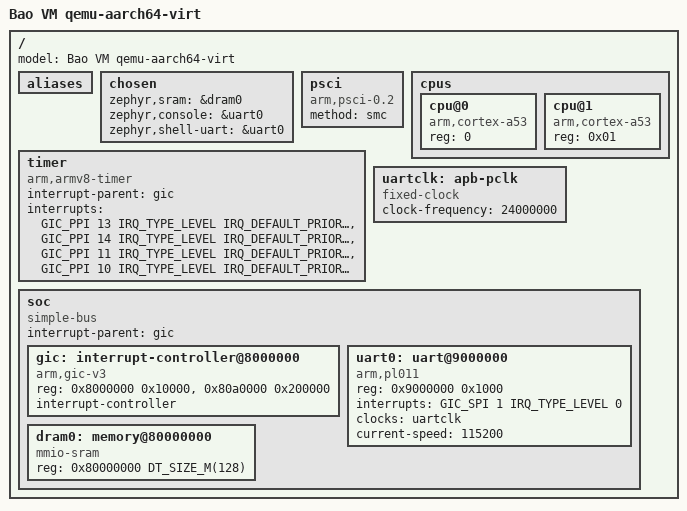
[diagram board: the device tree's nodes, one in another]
/*
 * Copyright (c) 2021 Carlo Caione <ccaione@baylibre.com>
 * SPDX-License-Identifier: Apache-2.0
 */

/dts-v1/;

#include <mem.h>
#include <zephyr/dt-bindings/interrupt-controller/arm-gic.h>

/ {
	model = "Bao VM qemu-aarch64-virt";
	#address-cells = <1>;
	#size-cells = <1>;

	aliases { };

	chosen {
		/*
		 * The SRAM node is actually located in the
		 * DRAM region of the FVP Base RevC 2xAEMv8A.
		 */
		zephyr,sram = &dram0;
		zephyr,console = &uart0;
		zephyr,shell-uart = &uart0;
	};

	psci {
		compatible = "arm,psci-0.2";
		method = "smc";
	};

	cpus {
		#address-cells = <1>;
		#size-cells = <0>;

		cpu@0 {
			device_type = "cpu";
			compatible = "arm,cortex-a53";
			reg = <0>;
		};

		cpu@1 {
			device_type = "cpu";
			compatible = "arm,cortex-a53";
			reg = <0x01>;
		};
	};

	timer {
		compatible = "arm,armv8-timer";
		interrupt-parent = <&gic>;
		interrupts = <GIC_PPI 13 IRQ_TYPE_LEVEL
			      IRQ_DEFAULT_PRIORITY>,
			     <GIC_PPI 14 IRQ_TYPE_LEVEL
			      IRQ_DEFAULT_PRIORITY>,
			     <GIC_PPI 11 IRQ_TYPE_LEVEL
			      IRQ_DEFAULT_PRIORITY>,
			     <GIC_PPI 10 IRQ_TYPE_LEVEL
			      IRQ_DEFAULT_PRIORITY>;
	};

	uartclk: apb-pclk {
		compatible = "fixed-clock";
		clock-frequency = <24000000>;
		#clock-cells = <0>;
	};

	soc {
		#address-cells = <1>;
		#size-cells = <1>;
		compatible = "simple-bus";
		ranges;
		interrupt-parent = <&gic>;

		gic: interrupt-controller@8000000 {
			compatible = "arm,gic-v3", "arm,gic";
			reg = <0x8000000 0x10000>, // GICD
			      <0x80a0000 0x200000>; // GICR
			interrupt-controller;
			#interrupt-cells = <4>;
			status = "okay";
			#address-cells = <1>;
			#size-cells = <1>;
		};

		uart0: uart@9000000 {
			compatible = "arm,pl011";
			reg = <0x9000000 0x1000>;
			status = "disabled";
			interrupts = <GIC_SPI 1 IRQ_TYPE_LEVEL 0>;
			interrupt-names = "irq_0";
			clocks = <&uartclk>;
		};

		dram0: memory@80000000 {
			compatible = "mmio-sram";
			reg = <0x80000000 DT_SIZE_M(128)>;
		};
	};
};

&uart0 {
	status = "okay";
	current-speed = <115200>;
};
